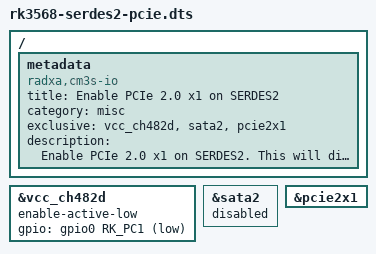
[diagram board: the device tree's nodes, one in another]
/dts-v1/;
/plugin/;

#include <dt-bindings/gpio/gpio.h>
#include <dt-bindings/pinctrl/rockchip.h>

/ {
	metadata {
		title = "Enable PCIe 2.0 x1 on SERDES2";
		compatible = "radxa,cm3s-io", "radxa,radxa-cm3-sodimm-io";
		category = "misc";
		exclusive = "vcc_ch482d", "sata2", "pcie2x1";
		description = "Enable PCIe 2.0 x1 on SERDES2.
This will disable SATA2.";
	};
};

&vcc_ch482d {
	enable-active-low;
	gpio = <&gpio0 RK_PC1 GPIO_ACTIVE_LOW>;
};

&sata2 {
	status = "disabled";
};

&pcie2x1 {
	status = "okay";
};
